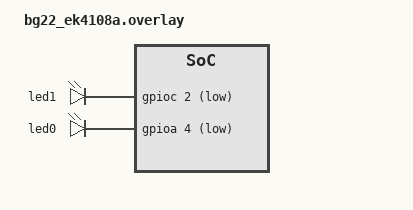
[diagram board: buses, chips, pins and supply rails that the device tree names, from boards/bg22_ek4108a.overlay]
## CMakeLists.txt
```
# SPDX-License-Identifier: Apache-2.0

cmake_minimum_required(VERSION 3.20.0)

find_package(Zephyr REQUIRED HINTS $ENV{ZEPHYR_BASE})
project(dl002)

target_sources(app PRIVATE src/main.c src/temperature.c src/ble.c src/hct6911.c src/pt100.c src/battery.c)
```

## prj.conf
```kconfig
# ---------------------------------------------------------------------------
# Console and logging: over RTT (J-Link), no UART
# ---------------------------------------------------------------------------
CONFIG_CONSOLE=y
CONFIG_USE_SEGGER_RTT=y
CONFIG_RTT_CONSOLE=y
CONFIG_UART_CONSOLE=n
# 1 KB for text waiting for the J-Link: keeps all boot lines even if the RTT viewer attaches late
CONFIG_SEGGER_RTT_BUFFER_SIZE_UP=1024
CONFIG_SEGGER_RTT_MAX_NUM_UP_BUFFERS=1

# Logging: LOG_ERR / LOG_WRN / LOG_INF with time and module name, printed at once (no log thread)
CONFIG_LOG=y
CONFIG_LOG_MODE_IMMEDIATE=y

# No float printing (%f): saves ~4.9 KB flash. Logs print values as whole numbers instead
CONFIG_CBPRINTF_FP_SUPPORT=n

# ---------------------------------------------------------------------------
# Hardware and power
# ---------------------------------------------------------------------------
# SPI to the HCT6911 temperature ADC
CONFIG_SPI=y

# Sleep (EM2) whenever all threads are idle
CONFIG_PM=y

# Battery voltage: the chip's ADC (IADC) measures its own supply (see dl002.dts)
CONFIG_ADC=y
# Interrupt stack: measured peak 480 B (thread analyzer, 2026-11-06), so 1024 leaves 2x.
# Pays for the ADC driver's 400 B of RAM
CONFIG_ISR_STACK_SIZE=1024

# ---------------------------------------------------------------------------
# Bluetooth: temperature advertising, and connectable for the first 15 s after power-on
# ---------------------------------------------------------------------------
CONFIG_BT=y
CONFIG_BT_BROADCASTER=y
CONFIG_BT_DEVICE_NAME="DL002-DFU"

# Connectable: a phone can connect (needed for DFU, also brings in GATT)
CONFIG_BT_PERIPHERAL=y
# One phone at a time
CONFIG_BT_MAX_CONN=1

# Scan: listen for other devices' advertisements (tested, not needed now)
#CONFIG_BT_OBSERVER=y

# RAM savings: features we don't use (we don't scan or pair). The Silabs controller takes its
# 6 KB buffer from the RAM left over at start-up, so every byte saved here counts
# 4 buffers for controller -> host events instead of 10. Saves ~700 B RAM
CONFIG_BT_BUF_EVT_RX_COUNT=4
# 1 buffer for scan reports instead of 3. Saves 140 B RAM
CONFIG_BT_BUF_EVT_DISCARDABLE_COUNT=1
# No GATT caching: the phone re-reads our service list on each connect.
# Saves ~1.5 KB RAM (no extra Bluetooth thread) and ~5 KB flash
CONFIG_BT_GATT_CACHING=n
# No "services changed" notice: our services never change. Saves ~940 B flash
CONFIG_BT_GATT_SERVICE_CHANGED=n
# Phone reading several values in one request: not needed for our 3 services
CONFIG_BT_GATT_READ_MULTIPLE=n
# Room for 4 crypto keys at once instead of 16. Saves 816 B RAM
CONFIG_MBEDTLS_PSA_KEY_SLOT_COUNT=4
# Bluetooth asserts still report, just without file/line text
CONFIG_BT_ASSERT_VERBOSE=n

# ---------------------------------------------------------------------------
# DFU: firmware update over BLE (MCUmgr SMP service, e.g. nRF Connect Device Manager).
# The new image goes into slot 1, MCUboot swaps it in on the next reset.
# CONFIG_FLASH is already in dl002_defconfig
# ---------------------------------------------------------------------------
CONFIG_MCUMGR=y
# MCUmgr messages are CBOR-encoded
CONFIG_ZCBOR=y
# Over BLE; long messages arrive in pieces and are put back together
CONFIG_MCUMGR_TRANSPORT_BT=y
CONFIG_MCUMGR_TRANSPORT_BT_REASSEMBLY=y
# 2 message buffers instead of 4: one for the incoming piece, one for the reply. Saves 768 B RAM.
# The phone must send one piece at a time (Device Manager: "Number of mcumgr buffers" = 1)
CONFIG_MCUMGR_TRANSPORT_NETBUF_COUNT=2
# OS commands (reset after an update). "echo" is not needed
CONFIG_MCUMGR_GRP_OS=y
CONFIG_MCUMGR_GRP_OS_ECHO=n
# Tell the phone our buffer count/size so it never sends more than fits
CONFIG_MCUMGR_GRP_OS_MCUMGR_PARAMS=y
# Image commands: upload, list, test, confirm
CONFIG_MCUMGR_GRP_IMG=y
# Write the received image into the slot 1 flash partition
CONFIG_IMG_MANAGER=y
CONFIG_STREAM_FLASH=y
CONFIG_FLASH_MAP=y
# Erase each flash sector just before writing it, instead of the whole slot at the start
CONFIG_IMG_ERASE_PROGRESSIVELY=y
```

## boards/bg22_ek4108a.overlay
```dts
/* DL002 LEDs (schematic "LED" box): VDD -> resistor -> LED -> MCU pin => active LOW */

/* Green LED, PA04. The dev kit already has led0 on PA04 (active HIGH), so only fix the polarity */
&led0 {
	gpios = <&gpioa 4 GPIO_ACTIVE_LOW>;
};

/ {
	leds {
		/* Red LED, PC02. The dev kit has no second LED, so add a new one */
		led1: led_1 {
			gpios = <&gpioc 2 GPIO_ACTIVE_LOW>;
		};
	};

	aliases {
		/* Short name so C code can find it with DT_ALIAS(led1) */
		led1 = &led1;
	};
};
```

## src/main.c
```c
#include <zephyr/logging/log.h>
#include <stdint.h>
#include <stdbool.h>
#include <zephyr/kernel.h>          /* k_msleep() */
#include <zephyr/drivers/gpio.h>    /* GPIO / LED functions */
#include "app_config.h"             /* DL002_ADV_* settings */
#include "temperature.h"            /* temperature_init(), temperature_read() */
#include "ble.h"                    /* ble_init(), ble_set_temperature(), ble_set_battery(), ble_adv_start() */
#include "battery.h"                /* battery_init(), battery_read_mv() */
#include <zephyr/dfu/mcuboot.h>     /* boot_is_img_confirmed(), boot_write_img_confirmed() */
#include <app_version.h>            /* APP_VERSION_STRING, from the VERSION file */

LOG_MODULE_REGISTER(main);

/* LED pin info from the devicetree (dl002.dts) */
static const struct gpio_dt_spec led_green = GPIO_DT_SPEC_GET(DT_ALIAS(led0), gpios);
static const struct gpio_dt_spec led_red   = GPIO_DT_SPEC_GET(DT_ALIAS(led1), gpios);

/* Button pin info from the devicetree (alias "sw0" -> PB01, active low, pull-up) */
static const struct gpio_dt_spec button = GPIO_DT_SPEC_GET(DT_ALIAS(sw0), gpios);

/* Holds our callback registration (Zephyr needs this to remember who to call) */
static struct gpio_callback button_cb;

static volatile int press_count;

/* Called by Zephyr the instant the button is pressed (runs in interrupt context) */
static void button_pressed(const struct device *dev, struct gpio_callback *cb, uint32_t pins)
{
	press_count++;
}

/* After a firmware update the new firmware runs "on trial": if the device resets before this
 * is called, MCUboot puts the old firmware back. Does nothing on normal boots.
 */
static void confirm_firmware(void)
{
	if (boot_is_img_confirmed()) {
		return;
	}

	int err = boot_write_img_confirmed();

	if (err) {
		LOG_ERR("Firmware confirm FAILED (err %d)", err);
		return;
	}
	LOG_INF("New firmware v%s confirmed", APP_VERSION_STRING);
}

int main(void)
{
	LOG_INF("DL002 firmware v%s", APP_VERSION_STRING);

	if (!gpio_is_ready_dt(&led_green) || !gpio_is_ready_dt(&led_red)) {
		LOG_ERR("LED GPIO not ready");
		return 0;
	}

	/* Both pins are outputs, both LEDs off (each one lit costs mA) */
	int err = gpio_pin_configure_dt(&led_green, GPIO_OUTPUT_INACTIVE);

	if (err) {
		LOG_ERR("Green LED pin configure FAILED (err %d)", err);
	}

	err = gpio_pin_configure_dt(&led_red, GPIO_OUTPUT_INACTIVE);
	if (err) {
		LOG_ERR("Red LED pin configure FAILED (err %d)", err);
	}

	if (!gpio_is_ready_dt(&button)) {
		LOG_ERR("Button GPIO not ready");
		return 0;
	}

	/* Make the pin an input (pull-up comes from the DTS flags) */
	gpio_pin_configure_dt(&button, GPIO_INPUT);

	/* Interrupt when the button becomes "active" = pressed */
	gpio_pin_interrupt_configure_dt(&button, GPIO_INT_EDGE_TO_ACTIVE);

	/* Tell Zephyr: on an interrupt for this pin, call button_pressed() */
	gpio_init_callback(&button_cb, button_pressed, BIT(button.pin));
	gpio_add_callback(button.port, &button_cb);

	/* On failure it prints why, and every temperature_read() gives TEMP_NO_READING */
	temperature_init();

	/* On failure it prints why, and every battery_read_mv() gives BATTERY_NO_READING */
	battery_init();

	/* On failure it prints why; without Bluetooth there is nothing to do */
	if (ble_init() != 0) {
		return 0;
	}

	/* No reading yet: advertise "no reading" rather than 0.00 °C / 0 V during the window */
	ble_set_temperature(TEMP_NO_READING);
	ble_set_battery(BATTERY_NO_READING);

	/* Connectable for DL002_CONNECTABLE_WINDOW_MS after power-on, so a phone can connect */
	if (ble_adv_start_connectable() == 0) {
		k_msleep(DL002_CONNECTABLE_WINDOW_MS);
		ble_adv_stop();
	}

	/* BLE works, so a phone could connect and send the next update: keep this firmware */
	confirm_firmware();

	LOG_INF("Advertising %d ms (packet every %d ms) every %d ms",
	        DL002_ADV_DURATION_MS, DL002_ADV_INTERVAL_MS, DL002_ADV_CYCLE_MS);

	int64_t last_reading_ms = 0;
	bool first_reading = true;

	while (1) {
		/* Temperature: a new reading on the first cycle, then once a minute has passed */
		if (first_reading || k_uptime_get() - last_reading_ms >= DL002_TEMP_MEASURE_INTERVAL_MS) {
			/* 0.01 °C, or TEMP_NO_READING (0x8000) if there is no valid reading */
			int16_t temp_centi_celsius = temperature_read();

			ble_set_temperature(temp_centi_celsius);
			ble_set_battery(battery_read_mv());
			last_reading_ms = k_uptime_get();
			first_reading = false;
		}

		/* Advertising: every cycle, with the latest temperature. On failure it prints why */
		ble_adv_start();

		/* The alarm stops advertising during this sleep; CONFIG_PM puts the chip in EM2 */
		k_msleep(DL002_ADV_CYCLE_MS);
	}

	return 0;
}
```

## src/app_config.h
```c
#ifndef APP_CONFIG_H
#define APP_CONFIG_H

#include <zephyr/toolchain.h>   /* BUILD_ASSERT() */

/* Each cycle: read the temperature if one is due, start advertising (an alarm stops it after
 * DL002_ADV_DURATION_MS), sleep DL002_ADV_CYCLE_MS
 */
#define DL002_ADV_INTERVAL_MS   20      /* time between packets while advertising (BLE min 20 ms) */
#define DL002_ADV_DURATION_MS   50     /* how long we advertise each cycle */
#define DL002_ADV_CYCLE_MS      1000    /* start of one cycle to the start of the next (+ reading time) */
#define DL002_ADV_TX_POWER_DBM  0       /* radio output power, max +6 dBm (lowest step -27.5) */

BUILD_ASSERT(DL002_ADV_DURATION_MS < DL002_ADV_CYCLE_MS, "advertising must be shorter than the cycle");

/* A new temperature reading at most every DL002_TEMP_MEASURE_INTERVAL_MS, checked once per cycle */
#define DL002_TEMP_MEASURE_INTERVAL_MS  60000   /* 1 min */

/* After power-on a phone can connect for this long (to configure the device later) */
#define DL002_CONNECTABLE_WINDOW_MS       15000   /* 15 s */
#define DL002_CONNECTABLE_ADV_INTERVAL_MS 100     /* one packet every 100 ms during the window */

#endif
```

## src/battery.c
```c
/*
 * Battery voltage. [SCH] The coin cell feeds the chip directly (BAT+ -> Q1 reverse-polarity
 * P-MOSFET -> VDD = AVDD/IOVDD), with no divider and no spare pin, so the chip's own ADC (IADC)
 * measures its supply (AVDD).
 */

#include <zephyr/logging/log.h>
#include <zephyr/drivers/adc.h>
#include <errno.h>          /* ENODEV */
#include <stdbool.h>
#include "battery.h"

LOG_MODULE_REGISTER(battery);

/* AVDD channel from the devicetree (zephyr,user io-channels in dl002.dts) */
static const struct adc_dt_spec avdd_channel = ADC_DT_SPEC_GET(DT_PATH(zephyr_user));

/* The IADC measures supply inputs divided by 4 ([RM] §24.3.5.2, Table 24.3: AVDD -> AVDD / 4) */
#define AVDD_INPUT_DIVIDER  4

static bool adc_ready;   /* false until battery_init() succeeds */

/* Set up the ADC channel. Returns 0, or a negative error (battery_read_mv() then always gives
 * BATTERY_NO_READING).
 */
int battery_init(void)
{
	if (!adc_is_ready_dt(&avdd_channel)) {
		LOG_ERR("Battery ADC not ready");
		return -ENODEV;
	}

	int err = adc_channel_setup_dt(&avdd_channel);

	if (err) {
		LOG_ERR("Battery ADC channel setup FAILED (err %d)", err);
		return err;
	}

	adc_ready = true;
	return 0;
}

/* One reading of the battery voltage in mV, or BATTERY_NO_READING on any failure */
uint16_t battery_read_mv(void)
{
	if (!adc_ready) {
		return BATTERY_NO_READING;
	}

	uint16_t adc_code;
	struct adc_sequence sequence = {
		.buffer = &adc_code,
		.buffer_size = sizeof(adc_code),
	};

	adc_sequence_init_dt(&avdd_channel, &sequence);

	int err = adc_read_dt(&avdd_channel, &sequence);

	if (err) {
		LOG_ERR("Battery ADC read FAILED (err %d)", err);
		return BATTERY_NO_READING;
	}

	/* ADC code -> mV at the ADC input (AVDD / 4), using the internal 1.21 V reference */
	int32_t input_mv = adc_code;

	err = adc_raw_to_millivolts_dt(&avdd_channel, &input_mv);
	if (err) {
		LOG_ERR("Battery ADC conversion FAILED (err %d)", err);
		return BATTERY_NO_READING;
	}

	uint16_t battery_mv = input_mv * AVDD_INPUT_DIVIDER;

	LOG_INF("Battery %u mV (ADC code %u)", battery_mv, adc_code);
	return battery_mv;
}
```

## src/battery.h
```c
#ifndef BATTERY_H
#define BATTERY_H

#include <stdint.h>

#define BATTERY_NO_READING  0   /* no valid reading (a real battery is never 0 mV) */

int battery_init(void);
uint16_t battery_read_mv(void);

#endif
```

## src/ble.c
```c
/*
 * Bluetooth: start the stack, set the TX power, build our advertisement and advertise for
 * DL002_ADV_DURATION_MS at a time.
 */

#include <zephyr/logging/log.h>
#include <stdint.h>
#include <errno.h>                  /* ENOENT */
#include <stdlib.h>                 /* abs() */
#include <zephyr/kernel.h>          /* k_work_schedule() */
#include <zephyr/sys/byteorder.h>   /* sys_put_be16(), sys_put_le16() */
#include <zephyr/sys/util.h>        /* MIN(), DIV_ROUND_CLOSEST() */
#include <zephyr/bluetooth/bluetooth.h>
#include <zephyr/bluetooth/conn.h>  /* BT_CONN_CB_DEFINE(), bt_conn_get_dst() */
#include "app_config.h"             /* DL002_ADV_* settings */
#include "ble.h"
#include "battery.h"                /* BATTERY_NO_READING */

LOG_MODULE_REGISTER(ble);

/* Manufacturer data, 13 bytes, as seen in nRF Connect:
 * F7 0E             company 0x0EF7 "Trackonomy Systems, Inc." (little-endian, set by the Bluetooth spec)
 * 52 58             Trackonomy marker (same as AL300)
 * D4 4A 85 BF 3E 17 MAC, same order as the boot log
 * 09 24             temperature, int16 big-endian, 0.01 °C (0x0924 = 2340 = 23.40 °C)
 * 1E                battery, 0.1 V (0x1E = 30 = 3.0 V), FF = no reading. Always the last byte
 */
#define TRACKONOMY_COMPANY_ID  0x0EF7
#define TRACKONOMY_MARKER      0x5258

#define MFG_COMPANY_OFFSET  0
#define MFG_MARKER_OFFSET   (MFG_COMPANY_OFFSET + sizeof(uint16_t))
#define MFG_MAC_OFFSET      (MFG_MARKER_OFFSET + sizeof(uint16_t))
#define MFG_TEMP_OFFSET     (MFG_MAC_OFFSET + BT_ADDR_SIZE)
#define MFG_BATTERY_OFFSET  (MFG_TEMP_OFFSET + sizeof(int16_t))
#define MFG_DATA_LEN        (MFG_BATTERY_OFFSET + sizeof(uint8_t))

#define MV_PER_DECIVOLT          100   /* battery byte is in 0.1 V steps */
#define BATTERY_BYTE_MAX         127   /* top bit stays 0, like the old tape's 8-bit battery type */
#define BATTERY_BYTE_NO_READING  0xFF  /* real readings are capped at 127, so FF can only mean this */

/* BG22 datasheet table 4.13 note 3: specified up to 6 dBm; above that, harmonics may exceed
 * regulatory limits. The Silabs library itself allows up to 8.5 dBm, so we limit it here.
 */
#define TX_POWER_MAX_DBM  6
#define DECI_DBM_PER_DBM  10      /* the Silabs library counts power in 0.1 dBm steps */

/* In the Silabs Bluetooth library, but not in any header: Zephyr's driver declares it the
 * same way (zephyr/drivers/bluetooth/hci/hci_silabs_efr32.c). Returns the power actually set.
 */
int16_t BTLE_LL_SetMaxPower(int16_t power);

/* Fixed part filled in ble_init(), temperature by ble_set_temperature() */
static uint8_t mfg_data[MFG_DATA_LEN];

static const struct bt_data ad[] = {
	BT_DATA_BYTES(BT_DATA_FLAGS, BT_LE_AD_NO_BREDR),
	BT_DATA(BT_DATA_MANUFACTURER_DATA, mfg_data, sizeof(mfg_data)),
};

/* Connectable window: "general discoverable" tells phones they may list us and connect */
static const struct bt_data ad_connectable[] = {
	BT_DATA_BYTES(BT_DATA_FLAGS, BT_LE_AD_GENERAL | BT_LE_AD_NO_BREDR),
	BT_DATA(BT_DATA_MANUFACTURER_DATA, mfg_data, sizeof(mfg_data)),
};

/* Scan response, sent only when a phone asks: our name (CONFIG_BT_DEVICE_NAME), so the phone lists us */
static const struct bt_data sd_connectable[] = {
	BT_DATA(BT_DATA_NAME_COMPLETE, CONFIG_BT_DEVICE_NAME, sizeof(CONFIG_BT_DEVICE_NAME) - 1),
};

/* Stop advertising (does nothing if we aren't advertising) */
void ble_adv_stop(void)
{
	int err = bt_le_adv_stop();

	if (err) {
		LOG_ERR("Advertising failed to stop (err %d)", err);
	}
}

/* Runs DL002_ADV_DURATION_MS after advertising starts (same idea as AL300's stop_adv_wk): radio off */
static void stop_adv_handler(struct k_work *work)
{
	ARG_UNUSED(work);
	ble_adv_stop();
}

static K_WORK_DELAYABLE_DEFINE(stop_adv_work, stop_adv_handler);

/* Called by the Bluetooth stack when a phone connects (or the attempt fails) */
static void connected(struct bt_conn *conn, uint8_t err)
{
	char address_text[BT_ADDR_LE_STR_LEN];

	bt_addr_le_to_str(bt_conn_get_dst(conn), address_text, sizeof(address_text));
	if (err) {
		LOG_ERR("Connection from %s failed (err 0x%02x)", address_text, err);
		return;
	}
	LOG_INF("Connected: %s", address_text);
}

/* Called when the connection ends; reason 0x13 = the phone disconnected */
static void disconnected(struct bt_conn *conn, uint8_t reason)
{
	char address_text[BT_ADDR_LE_STR_LEN];

	bt_addr_le_to_str(bt_conn_get_dst(conn), address_text, sizeof(address_text));
	LOG_INF("Disconnected: %s (reason 0x%02x)", address_text, reason);
}

BT_CONN_CB_DEFINE(conn_callbacks) = {
	.connected = connected,
	.disconnected = disconnected,
};

/* Set the Bluetooth TX power (at most TX_POWER_MAX_DBM). The radio uses the nearest step at or
 * just below the request (lowest step -27.5 dBm); the Silabs library returns that step, so we
 * print it. Call after bt_enable().
 */
static void ble_set_tx_power(int8_t requested_dbm)
{
	int8_t allowed_dbm = MIN(requested_dbm, TX_POWER_MAX_DBM);

	if (allowed_dbm != requested_dbm) {
		LOG_WRN("TX power %d dBm is above the %d dBm limit, using %d dBm",
		        requested_dbm, TX_POWER_MAX_DBM, allowed_dbm);
	}

	int16_t set_deci_dbm = BTLE_LL_SetMaxPower(allowed_dbm * DECI_DBM_PER_DBM);
	int set_deci_dbm_abs = abs(set_deci_dbm);

	/* Whole numbers, no %f: -275 -> "-27.5" */
	LOG_INF("TX power: requested %d dBm, radio uses %s%d.%d dBm",
	        allowed_dbm, (set_deci_dbm < 0) ? "-" : "",
	        set_deci_dbm_abs / DECI_DBM_PER_DBM, set_deci_dbm_abs % DECI_DBM_PER_DBM);
}

/* Start the Bluetooth stack, set the TX power and fill the fixed part of the advertisement
 * (company ID, marker, MAC). Returns 0, the bt_enable() error, or -ENOENT if there is no address.
 */
int ble_init(void)
{
	/* Start the Bluetooth stack (radio library, controller) */
	int err = bt_enable(NULL);

	if (err) {
		LOG_ERR("Bluetooth init failed (err %d)", err);
		return err;
	}
	LOG_INF("Bluetooth initialized");

	ble_set_tx_power(DL002_ADV_TX_POWER_DBM);   /* prints the power the radio actually uses */

	/* Our own (identity) address, e.g. D4:4A:85:BF:3E:17 (public) */
	bt_addr_le_t identity_address;
	size_t identity_count = 1;
	char address_text[BT_ADDR_LE_STR_LEN];

	bt_id_get(&identity_address, &identity_count);
	if (identity_count == 0) {
		LOG_ERR("Bluetooth address FAILED: no identity address");
		return -ENOENT;
	}
	bt_addr_le_to_str(&identity_address, address_text, sizeof(address_text));
	LOG_INF("Bluetooth address %s", address_text);

	/* Fixed part of the advertisement: company ID (little-endian, Bluetooth spec), then the marker */
	sys_put_le16(TRACKONOMY_COMPANY_ID, &mfg_data[MFG_COMPANY_OFFSET]);
	sys_put_be16(TRACKONOMY_MARKER, &mfg_data[MFG_MARKER_OFFSET]);

	/* Copy the MAC into the advertisement. Zephyr stores it reversed, so val[5] goes first
	 * to make it read the same as the boot log.
	 */
	for (int byte_index = 0; byte_index < BT_ADDR_SIZE; byte_index++) {
		mfg_data[MFG_MAC_OFFSET + byte_index] = identity_address.a.val[BT_ADDR_SIZE - 1 - byte_index];
	}
	return 0;
}

/* Put the temperature into the advertisement (big-endian: 2340 -> 09 24).
 * Goes on air from the next ble_adv_start().
 */
void ble_set_temperature(int16_t temp_centi_celsius)
{
	sys_put_be16((uint16_t)temp_centi_celsius, &mfg_data[MFG_TEMP_OFFSET]);
}

/* Put the battery voltage into the advertisement, in 0.1 V steps: 3008 mV -> 30 (0x1E).
 * No reading (BATTERY_NO_READING) -> FF. Goes on air from the next ble_adv_start().
 */
void ble_set_battery(uint16_t battery_mv)
{
	if (battery_mv == BATTERY_NO_READING) {
		mfg_data[MFG_BATTERY_OFFSET] = BATTERY_BYTE_NO_READING;
		return;
	}

	/* Rounded to the nearest 0.1 V (2990 mV -> 30); plain division would always round down (29) */
	uint32_t battery_decivolts = DIV_ROUND_CLOSEST(battery_mv, MV_PER_DECIVOLT);

	/* Capped so it fits the byte without wrapping, and can never be mistaken for FF */
	mfg_data[MFG_BATTERY_OFFSET] = MIN(battery_decivolts, BATTERY_BYTE_MAX);
}

/* Start advertising: non-connectable, fixed identity address, one packet every
 * DL002_ADV_INTERVAL_MS. An alarm stops it after DL002_ADV_DURATION_MS.
 * Returns 0, or the bt_le_adv_start() error.
 */
int ble_adv_start(void)
{
	int err = bt_le_adv_start(BT_LE_ADV_PARAM(BT_LE_ADV_OPT_USE_IDENTITY,
						  BT_GAP_MS_TO_ADV_INTERVAL(DL002_ADV_INTERVAL_MS),
						  BT_GAP_MS_TO_ADV_INTERVAL(DL002_ADV_INTERVAL_MS), NULL),
				  ad, ARRAY_SIZE(ad), NULL, 0);

	if (err) {
		LOG_ERR("Advertising failed to start (err %d)", err);
		return err;
	}

	/* Alarm: stop advertising after DL002_ADV_DURATION_MS */
	k_work_schedule(&stop_adv_work, K_MSEC(DL002_ADV_DURATION_MS));
	return 0;
}

/* Start connectable advertising (one packet every DL002_CONNECTABLE_ADV_INTERVAL_MS).
 * Runs until ble_adv_stop(), or until a phone connects (then the stack stops it).
 * Returns 0, or the bt_le_adv_start() error.
 */
int ble_adv_start_connectable(void)
{
	int err = bt_le_adv_start(BT_LE_ADV_PARAM(BT_LE_ADV_OPT_CONN | BT_LE_ADV_OPT_USE_IDENTITY,
						  BT_GAP_MS_TO_ADV_INTERVAL(DL002_CONNECTABLE_ADV_INTERVAL_MS),
						  BT_GAP_MS_TO_ADV_INTERVAL(DL002_CONNECTABLE_ADV_INTERVAL_MS), NULL),
				  ad_connectable, ARRAY_SIZE(ad_connectable),
				  sd_connectable, ARRAY_SIZE(sd_connectable));

	if (err) {
		LOG_ERR("Connectable advertising failed to start (err %d)", err);
		return err;
	}
	LOG_INF("Connectable for %d ms", DL002_CONNECTABLE_WINDOW_MS);
	return 0;
}
```

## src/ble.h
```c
#ifndef BLE_H
#define BLE_H

#include <stdint.h>

int ble_init(void);
void ble_set_temperature(int16_t temp_centi_celsius);
void ble_set_battery(uint16_t battery_mv);
int ble_adv_start(void);
int ble_adv_start_connectable(void);
void ble_adv_stop(void);

#endif
```

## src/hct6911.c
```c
/*
 * HCT6911 24-bit ADC: SPI register access, PT100 configuration and measurement, sleep/wake.
 * [HCT] = HCT6911 datasheet, printed page numbers (English translation: HCT6911_datasheet_EN_full.pdf).
 */

#include <zephyr/logging/log.h>
#include <zephyr/kernel.h>
#include <zephyr/drivers/spi.h>
#include <zephyr/drivers/gpio.h>
#include <zephyr/sys/byteorder.h>	/* sys_get_be24/32, sys_put_be24/32 */
#include "hct6911.h"

LOG_MODULE_REGISTER(hct6911);

/* Timing */
#define HCT6911_RESET_WAIT_MS    15	/* reset takes 10 ms ([HCT] p.40) + margin */
#define HCT6911_WAKE_US          200	/* wait after POWD=0 before a conversion ([HCT] p.20) */
#define HCT6911_CONV_TIMEOUT_MS  500	/* one result takes ~120 ms ([HCT] p.19), so ~4x margin */

/* SPI mode 0 (no CPOL/CPHA flags): SCLK idles low, sampled on rising edge ([HCT] p.31-32) */
static const struct spi_dt_spec hct = SPI_DT_SPEC_GET(DT_NODELABEL(hct6911),
						      SPI_WORD_SET(8) | SPI_TRANSFER_MSB);

/* Same device, but CS stays LOW between calls until spi_release_dt().
 * A conversion frame needs CS low from the command until the data is read ([HCT] p.26, Fig 4-7).
 */
static const struct spi_dt_spec hct_conv = SPI_DT_SPEC_GET(DT_NODELABEL(hct6911),
							   SPI_WORD_SET(8) | SPI_TRANSFER_MSB |
							   SPI_HOLD_ON_CS | SPI_LOCK_ON);

/* DOUT/DRDY# shares the MISO pin: it goes LOW when a conversion result is ready */
static const struct gpio_dt_spec drdy = GPIO_DT_SPEC_GET(DT_NODELABEL(hct6911), drdy_gpios);

/*
 * Command byte ([HCT] p.21, Table 4-1/4-2):
 *   bit 7    = 0 (read/write frame)
 *   bits 6:2 = register address
 *   bit 1    = 1 read, 0 write
 *   bit 0    = odd parity: makes the total number of 1s in the byte odd
 */
static uint8_t hct6911_cmd(uint8_t addr, bool read)
{
	uint8_t cmd = (addr << 2) | (read ? BIT(1) : 0);

	if (__builtin_popcount(cmd) % 2 == 0) {
		cmd |= BIT(0);
	}
	return cmd;
}

/*
 * Read one HCT6911 register.
 *   addr:   register address, e.g. HCT6911_SYS_CONF0
 *   nbytes: register size, HCT6911_REG_24BIT or HCT6911_REG_32BIT
 *   value:  where to store the result (pass &my_variable)
 * Returns 0 on success, or a negative SPI error code.
 *
 * On the wire ([HCT] p.24, Fig 4-3/4-4), CS low for the whole frame:
 *   MOSI: [read command] [00] [00] [00] ([00])
 *   MISO: [junk        ] [data, biggest byte first]
 */
int hct6911_read_reg(uint8_t addr, int nbytes, uint32_t *value)
{
	uint8_t tx[1 + HCT6911_REG_32BIT] = { hct6911_cmd(addr, true) };	/* rest is 0x00 while we listen */
	uint8_t rx[1 + HCT6911_REG_32BIT];
	const struct spi_buf tx_buf = { .buf = tx, .len = 1 + nbytes };
	const struct spi_buf rx_buf = { .buf = rx, .len = 1 + nbytes };
	const struct spi_buf_set tx_set = { .buffers = &tx_buf, .count = 1 };
	const struct spi_buf_set rx_set = { .buffers = &rx_buf, .count = 1 };

	int err = spi_transceive_dt(&hct, &tx_set, &rx_set);

	/* rx[0] arrived while the chip was still receiving the command: skip it */
	if (nbytes == HCT6911_REG_32BIT) {
		*value = sys_get_be32(&rx[1]);
	} else {
		*value = sys_get_be24(&rx[1]);
	}
	return err;
}

/*
 * Write one HCT6911 register.
 *   addr:   register address, e.g. HCT6911_CONV_CONF0
 *   nbytes: register size, HCT6911_REG_24BIT or HCT6911_REG_32BIT
 *   value:  the new register value
 * Returns 0 on success, or a negative SPI error code.
 *
 * On the wire ([HCT] p.23, Fig 4-1/4-2), CS low for the whole frame:
 *   MOSI: [write command] [data, biggest byte first]
 */
int hct6911_write_reg(uint8_t addr, int nbytes, uint32_t value)
{
	uint8_t tx[1 + HCT6911_REG_32BIT] = { hct6911_cmd(addr, false) };

	if (nbytes == HCT6911_REG_32BIT) {
		sys_put_be32(value, &tx[1]);
	} else {
		sys_put_be24(value, &tx[1]);
	}

	const struct spi_buf tx_buf = { .buf = tx, .len = 1 + nbytes };
	const struct spi_buf_set tx_set = { .buffers = &tx_buf, .count = 1 };

	return spi_write_dt(&hct, &tx_set);
}

/* One-time set-up: check the SPI bus and the DRDY pin, and configure the DRDY pin as an input.
 * gpio_pin_configure_dt() is what makes GPIO_ACTIVE_LOW take effect for gpio_pin_get_dt().
 */
int hct6911_init(void)
{
	if (!spi_is_ready_dt(&hct)) {
		LOG_ERR("init FAILED: SPI bus not ready");
		return -ENODEV;
	}
	if (!gpio_is_ready_dt(&drdy)) {
		LOG_ERR("init FAILED: DRDY GPIO port not ready");
		return -ENODEV;
	}
	int err = gpio_pin_configure_dt(&drdy, GPIO_INPUT);

	if (err) {
		LOG_ERR("init FAILED: DRDY pin configure error %d", err);
	}
	return err;
}

/* Step 4.1: global reset. Write 1 to SYS_CONF0 bit 31 RS_SYS; it clears itself after 10 ms
 * ([HCT] p.40, Table 5-6; procedure step 1 on p.60).
 * On failure: prints why and returns a negative error code.
 */
int hct6911_reset(void)
{
	uint32_t sys_conf0;

	int err = hct6911_write_reg(HCT6911_SYS_CONF0, HCT6911_REG_32BIT, HCT6911_SYS_CONF0_RS_SYS);

	if (err) {
		LOG_ERR("reset FAILED: SPI error %d", err);
		return err;
	}
	k_msleep(HCT6911_RESET_WAIT_MS);

	err = hct6911_read_reg(HCT6911_SYS_CONF0, HCT6911_REG_32BIT, &sys_conf0);
	if (err) {
		LOG_ERR("reset FAILED: SPI error %d", err);
		return err;
	}

	bool reset_still_running = (sys_conf0 & HCT6911_SYS_CONF0_RS_SYS) != 0;
	bool reset_succeeded     = (sys_conf0 & HCT6911_SYS_CONF0_RS_V) != 0;

	if (reset_still_running || !reset_succeeded) {
		LOG_ERR("reset FAILED: SYS_CONF0 = 0x%08X (expected 0x00008000)", sys_conf0);
		return -EIO;
	}
	return 0;
}

/* Write a 32-bit register, read it back and compare.
 * On failure: prints what went wrong and returns a negative error code.
 */
static int write_reg32_and_verify(uint8_t addr, uint32_t value)
{
	uint32_t readback;

	int err = hct6911_write_reg(addr, HCT6911_REG_32BIT, value);

	if (err) {
		LOG_ERR("write register 0x%02X FAILED: SPI error %d", addr, err);
		return err;
	}
	err = hct6911_read_reg(addr, HCT6911_REG_32BIT, &readback);
	if (err) {
		LOG_ERR("read register 0x%02X FAILED: SPI error %d", addr, err);
		return err;
	}
	if (readback != value) {
		LOG_ERR("register 0x%02X FAILED: read back 0x%08X, wrote 0x%08X",
		        addr, readback, value);
		return -EIO;
	}
	return 0;
}

/*
 * Step 4.2: configure for the DL002's 4-wire PT100 ([HCT] p.60, procedure steps 2-3), using
 * this board's HCT6911 pin names ([HCT] p.14-15, Table 2-1):
 *   IDAC0 1 mA out of AIN0 (pin 6) -> RTD_B2 -> PT100 -> RTD_A1 -> R74 1.62k -> GND
 *   measure AIN5 (pin 10, RTD_B1) minus AIN6 (pin 11, RTD_A2)
 *   reference REFP1/REFN1 (pins 9/8) = voltage across R74
 * On failure: prints why and returns a negative error code.
 */
int hct6911_setup_pt100(void)
{
	/* CONV_CONF0 fields: [HCT] p.36-39, Table 5-5 */
	uint32_t conv_conf0 =
		BIT(31) |		/* CONV_EN: use this conversion setting */
		(0x8 << 20) |		/* DR: 25 Hz data rate */
		(0x1 << 16) |		/* FLIT_TYPE: 3rd-order filter */
		(0x0 << 14) |		/* REFSEL: REFP1/REFN1 = across R74 */
					/* bits 13/12 = 0: signal + reference buffers ON (default) */
		(0x3 << 8) |		/* GA: gain x8 (schematic) */
		(0x6 << 4) |		/* VNSEL: negative input = AIN6 (pin 11) */
		(0x5 << 0);		/* VPSEL: positive input = AIN5 (pin 10) */

	/* SYS_CONF2 fields: [HCT] p.45-46, Table 5-8 */
	uint32_t sys_conf2 =
		(0x0 << 8) |		/* IDAC0_CH: current out of AIN0 (pin 6) */
		(0x5 << 0);		/* IDAC0: 1000 uA (schematic) */

	int err = write_reg32_and_verify(HCT6911_CONV_CONF0, conv_conf0);

	if (err) {
		return err;
	}

	err = write_reg32_and_verify(HCT6911_SYS_CONF2, sys_conf2);

	return err;
}

/* Sleep, < 1 uA ([HCT] §3.12 p.20). The datasheet doesn't list the excitation current as switched
 * off by POWD, so set IDAC0 to 0 uA first (§3.7 p.18). Registers are kept while asleep.
 */
int hct6911_sleep(void)
{
	int err = write_reg32_and_verify(HCT6911_SYS_CONF2, 0);	/* IDAC0 = 0 uA */

	if (err) {
		return err;
	}
	err = write_reg32_and_verify(HCT6911_SYS_CONF1, HCT6911_SYS_CONF1_POWD);
	
	return err;
}

/* Wake up: POWD = 0, then wait before converting ([HCT] p.20).
 * hct6911_setup_pt100() turns the 1 mA excitation current back on.
 */
int hct6911_wake(void)
{
	int err = write_reg32_and_verify(HCT6911_SYS_CONF1, 0);

	if (err) {
		return err;
	}
	k_busy_wait(HCT6911_WAKE_US);
	return 0;
}

/*
 * DOUT/DRDY# (pin 15) is read on PC03 (= MISO) while the chip converts ([HCT] p.26):
 *   busy  = chip has released the pin, R82 1 MΩ pulls it HIGH
 *   ready = chip pulls it LOW, result can be clocked out
 * drdy is GPIO_ACTIVE_LOW in the DTS, so gpio_pin_get_dt() returns 1 when ready.
 */
static bool drdy_is_ready(void)
{
	return gpio_pin_get_dt(&drdy) == 1;
}

/* Poll DRDY every 1 ms until the result is ready. Returns the ms waited, or -ETIMEDOUT. */
static int wait_until_ready(int timeout_ms)
{
	for (int waited_ms = 0; waited_ms <= timeout_ms; waited_ms++) {
		if (drdy_is_ready()) {
			return waited_ms;
		}
		k_msleep(1);
	}
	return -ETIMEDOUT;
}

/*
 * Step 4.3: one single conversion ([HCT] p.25-26, Table 4-4/4-5, Fig 4-7).
 * CS is held LOW from the start command until the result has been read.
 *   1. before start: DOUT is HIGH (idle, R82 pull-up)
 *   2. send CMD_SINGLE_CONVERSION (0x80) = "start measuring"
 *   3. wait for DOUT LOW = result ready (~120 ms at 25 Hz, 3rd-order filter, [HCT] p.19)
 *   4. send CMD_READ_RESULT (0x42) = "send me the result", clock in 24 bits, CS HIGH
 *   5. SYS_CONF0 CKS_ERR = 0: no command byte was rejected ([HCT] p.41)
 * On failure: prints which step failed and returns a negative error code.
 */
int hct6911_read_raw(int32_t *code)
{
	uint8_t cmd = HCT6911_CMD_SINGLE_CONVERSION;
	const struct spi_buf cmd_buf = { .buf = &cmd, .len = 1 };
	const struct spi_buf_set cmd_set = { .buffers = &cmd_buf, .count = 1 };

	uint8_t tx[1 + HCT6911_RESULT_BYTES] = { HCT6911_CMD_READ_RESULT };	/* rest is 0x00 while we listen */
	uint8_t rx[1 + HCT6911_RESULT_BYTES];
	const struct spi_buf tx_buf = { .buf = tx, .len = sizeof(tx) };
	const struct spi_buf rx_buf = { .buf = rx, .len = sizeof(rx) };
	const struct spi_buf_set tx_set = { .buffers = &tx_buf, .count = 1 };
	const struct spi_buf_set rx_set = { .buffers = &rx_buf, .count = 1 };

	/* 1. Idle line must be HIGH before we start */
	if (drdy_is_ready()) {
		LOG_ERR("step 1 FAILED: DOUT is LOW before start (expected HIGH)");
		return -EIO;
	}

	/* 2. Send the single-conversion command; CS stays LOW (hct_conv has SPI_HOLD_ON_CS) */
	int err = spi_write_dt(&hct_conv, &cmd_set);

	if (err) {
		spi_release_dt(&hct_conv);
		LOG_ERR("step 2 FAILED: SPI error %d sending the conversion command", err);
		return err;
	}

	/* 3. Wait for DOUT LOW = result ready */
	int ready_ms = wait_until_ready(HCT6911_CONV_TIMEOUT_MS);

	if (ready_ms < 0) {
		spi_release_dt(&hct_conv);
		LOG_ERR("step 3 FAILED: no result within %d ms", HCT6911_CONV_TIMEOUT_MS);
		return -ETIMEDOUT;
	}

	/* 4. Send CMD_READ_RESULT and read the 24-bit result, then CS HIGH to end the frame */
	err = spi_transceive_dt(&hct_conv, &tx_set, &rx_set);
	spi_release_dt(&hct_conv);
	if (err) {
		LOG_ERR("step 4 FAILED: SPI error %d reading data", err);
		return err;
	}

	/* 5. Did the chip reject any command byte? (reading SYS_CONF0 also clears the flag) */
	uint32_t sys_conf0;

	err = hct6911_read_reg(HCT6911_SYS_CONF0, HCT6911_REG_32BIT, &sys_conf0);
	if (err) {
		LOG_ERR("step 5 FAILED: SPI error %d reading SYS_CONF0", err);
		return err;
	}
	if (sys_conf0 & HCT6911_SYS_CONF0_CKS_ERR) {
		LOG_ERR("step 5 FAILED: CKS_ERR set, SYS_CONF0 = 0x%08X", sys_conf0);
		return -EIO;
	}

	/* rx[0] arrived during the CMD_READ_RESULT byte: skip it.
	 * Result is 24-bit signed, biggest byte first; bit 23 is the sign bit ([HCT] p.49).
	 */
	*code = sign_extend(sys_get_be24(&rx[1]), 23);
	return 0;
}
```

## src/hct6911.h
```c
#ifndef HCT6911_H
#define HCT6911_H

#include <stdint.h>
#include <zephyr/sys/util.h>	/* BIT() */

/* Register addresses ([HCT] p.33-34, Table 5-1) */
#define HCT6911_OS_CH0     0x00	/* 24 bit, R/W, default 0x000000 */
#define HCT6911_GAIN_CH0   0x01	/* 24 bit, R/W, default 0x400000 */
#define HCT6911_D_TARG     0x10	/* 24 bit, R/W, default 0x7FFFFF */
#define HCT6911_CONV_CONF0 0x11	/* 32 bit, R/W, default 0x00000000 */
#define HCT6911_SYS_CONF0  0x1B	/* 32 bit, R/W, default 0x00008000 */
#define HCT6911_SYS_CONF1  0x1C	/* 32 bit, R/W, default 0x00000000 */
#define HCT6911_SYS_CONF2  0x1D	/* 32 bit, R/W, default 0x00000000 */

/* Register sizes in bytes ([HCT] p.33-34, Table 5-1) */
#define HCT6911_REG_24BIT  3
#define HCT6911_REG_32BIT  4

/* Conversion frame ([HCT] p.25-26, Table 4-4, Fig 4-7) */
#define HCT6911_CMD_SINGLE_CONVERSION  0x80	/* bit 7 = 1 conversion frame, CONV_MOD 0 = single, parity 0 */
#define HCT6911_CMD_READ_RESULT        0x42	/* must be sent in the 8 clocks before the result */
#define HCT6911_RESULT_BYTES           3	/* result is 24-bit signed ([HCT] p.49) */

/* SYS_CONF0 bits ([HCT] p.40-42, Table 5-6) */
#define HCT6911_SYS_CONF0_RS_SYS   BIT(31)	/* write 1 = start reset; reads 1 while resetting */
#define HCT6911_SYS_CONF0_RS_V     BIT(15)	/* 1 = last reset succeeded */
#define HCT6911_SYS_CONF0_CKS_ERR  BIT(10)	/* 1 = a command byte was rejected (parity/CRC) */
#define HCT6911_SYS_CONF1_POWD     BIT(15)	/* 1 = sleep, < 1 uA ([HCT] p.20, p.44) */

int hct6911_read_reg(uint8_t addr, int nbytes, uint32_t *value);
int hct6911_write_reg(uint8_t addr, int nbytes, uint32_t value);

int hct6911_init(void);
int hct6911_reset(void);
int hct6911_setup_pt100(void);
int hct6911_read_raw(int32_t *code);
int hct6911_sleep(void);
int hct6911_wake(void);

#endif
```

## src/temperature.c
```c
/*
 * Temperature: the HCT6911 ADC (hct6911.c) and the PT100 maths (pt100.c) put together.
 * Gives the temperature in 0.01 °C, or TEMP_NO_READING.
 */

#include <zephyr/logging/log.h>
#include <stdbool.h>
#include <errno.h>       /* EIO */
#include <math.h>        /* lroundf() */
#include <stdlib.h>      /* abs() */
#include "hct6911.h"     /* temperature ADC (PT100 front end) */
#include "pt100.h"       /* code -> ohm -> °C */
#include "temperature.h"

LOG_MODULE_REGISTER(temperature);

static bool adc_ready;   /* false until temperature_init() succeeds */

/* Temperature ADC (powered from boot, see adc_3v3 in dl002.dts): init, wake, reset,
 * configure for the PT100, then sleep until the first reading.
 * Wake first: after a reset without a power cycle (e.g. flashing), the HCT6911 can still be
 * asleep from the previous run, and a sleeping HCT6911 ignores a reset ([HCT] p.20).
 * Stops at the first failing step; that function prints why.
 * Returns 0 on success, -EIO if any step failed (temperature_read() then always gives
 * TEMP_NO_READING).
 */
int temperature_init(void)
{
	adc_ready = (hct6911_init() == 0) &&
		    (hct6911_wake() == 0) &&
		    (hct6911_reset() == 0) &&
		    (hct6911_setup_pt100() == 0) &&
		    (hct6911_sleep() == 0);

	if (!adc_ready) {
		LOG_ERR("HCT6911 not ready: no temperature readings");
		return -EIO;
	}
	return 0;
}

/* Wake the HCT6911, turn the excitation current back on (setup_pt100), take one reading and put
 * it back to sleep. Returns the temperature in 0.01 °C, or TEMP_NO_READING on any failure
 * (the function that failed has already printed why).
 */
int16_t temperature_read(void)
{
	if (!adc_ready) {
		return TEMP_NO_READING;
	}

	int32_t pt100_code;
	bool reading_ok = (hct6911_wake() == 0) &&
			  (hct6911_setup_pt100() == 0) &&
			  (hct6911_read_raw(&pt100_code) == 0);

	/* Back to sleep (< 1 uA) even if the reading failed */
	hct6911_sleep();

	if (!reading_ok) {
		return TEMP_NO_READING;
	}

	float r_ohm = pt100_code_to_ohm(pt100_code);
	float temp_c = pt100_ohm_to_celsius(r_ohm);

	/* For the logs: whole numbers, no %f (printing floats costs ~5 KB of flash) */
	int r_milliohm = (int)lroundf(r_ohm * 1000.0f);
	int r_milliohm_abs = abs(r_milliohm);

	if (temp_c < PT100_MIN_CELSIUS || temp_c > PT100_MAX_CELSIUS) {
		LOG_WRN("PT100 out of range: R = %s%d.%03d ohm (probe unplugged or shorted?)",
		        (r_milliohm < 0) ? "-" : "", r_milliohm_abs / 1000, r_milliohm_abs % 1000);
		return TEMP_NO_READING;
	}

	/* 23.40 °C -> 2340 (rounded, so 23.3999 doesn't become 2339) */
	int16_t temp_centi_celsius = (int16_t)lroundf(temp_c * 100.0f);
	int temp_abs = abs(temp_centi_celsius);

	LOG_INF("PT100 R = %d.%03d ohm, T = %s%d.%02d C",
	        r_milliohm_abs / 1000, r_milliohm_abs % 1000,
	        (temp_centi_celsius < 0) ? "-" : "", temp_abs / 100, temp_abs % 100);
	return temp_centi_celsius;
}
```

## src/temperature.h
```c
#ifndef TEMPERATURE_H
#define TEMPERATURE_H

#include <stdint.h>

#define TEMP_NO_READING  INT16_MIN   /* 0x8000: no valid reading */

int temperature_init(void);
int16_t temperature_read(void);

#endif
```
